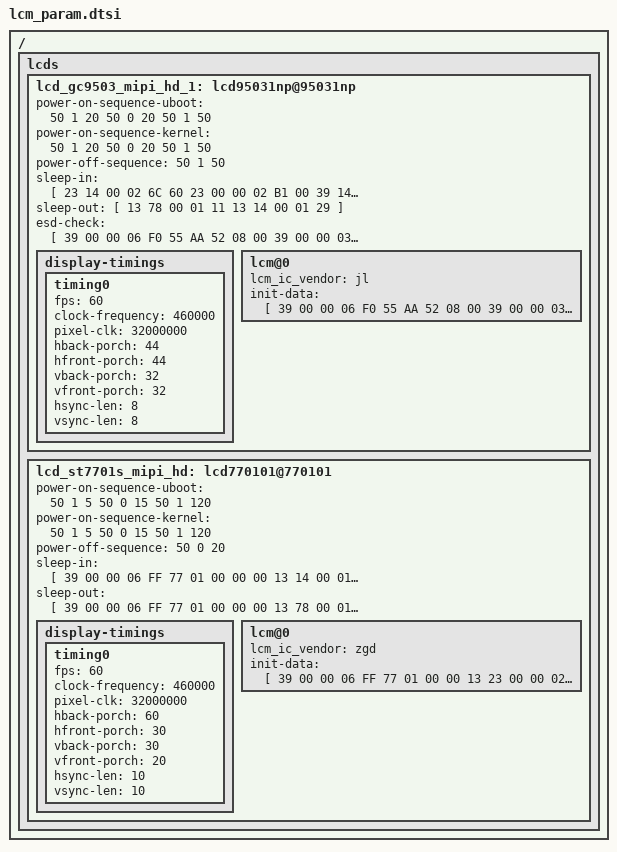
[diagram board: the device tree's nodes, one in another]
/ {
	lcds {

		lcd_gc9503_mipi_hd_1: lcd95031np@95031np {

		power-on-sequence-uboot = <//first level second delay ms
					50  1  20
					50  0  20
					50  1  50
					>;

		power-on-sequence-kernel = <
					50  1  20
					50  0  20
					50  1  50
					>;

		power-off-sequence = <
					50  1  50
					>;

		sleep-in = [
			23 14 00 02 6C 60
			23 00 00 02 B1 00
			39 14 00 05 FA 7F 00 00 00
			23 0a 00 02 6c 50
			23 32 00 02 28 00
			23 78 00 02 10 00
			39 00 00 06 F0 55 aa 52 08 00
			23 00 00 02 c2 ce
			23 00 00 02 c3 cd
			23 00 00 02 c6 fc
			23 00 00 02 c5 03
			23 00 00 02 cd 64
			23 00 00 02 c4 ff
			23 00 00 02 c9 cd
			39 00 00 03 F6 5a 87
			39 00 00 04 Fd aa aa 0a
			39 00 00 03 Fe 6a 0a
			39 00 00 03 78 2a aa
			39 00 00 03 92 17 08
			39 00 00 03 77 aa 2a
			39 00 00 03 76 aa aa
			23 00 00 02 84 00
			39 00 00 03 78 2b ba
			23 00 00 02 89 73
			23 00 00 02 88 3A
			23 00 00 02 85 B0
			39 00 00 03 76 eb aa
			23 00 00 02 94 80
			39 00 00 04 87 04 07 30
			23 00 00 02 93 27
			23 00 00 02 af 02
			];

		sleep-out = [
			13 78 00 01 11
			13 14 00 01 29
			];

		esd-check = [
			39 00 00 06 F0 55 AA 52 08 00
			39 00 00 03 F6 5A 87
			23 00 00 02 C1 3F
			23 00 00 02 C2 0E
			23 00 00 02 C6 F8
			23 00 00 02 C9 10
			23 00 00 02 CD 25
			39 00 00 04 87 04 03 66
			39 00 00 05 86 99 a3 a3 51
			23 00 00 02 F8 8A
			23 00 00 02 AC 45
			23 00 00 02 A7 47
			23 00 00 02 A0 dd
			39 00 00 05 FA 08 08 00 04
			23 00 00 02 A3 2E
			39 00 00 04 FD 28 3c 00
			23 00 00 02 71 48
			23 00 00 02 72 48
			39 00 00 03 73 00 44
			23 00 00 02 97 EE
			23 00 00 02 83 93
			23 00 00 02 B1 10
			39 00 00 03 7A 13 1A
			39 00 00 03 7B 13 1A
			39 00 00 11 64 18 09 03 59 03 03 18 08 03 5A 03 03 7A 7A 7A 7A
			39 00 00 11 67 18 07 03 5B 03 03 18 06 03 5C 03 03 7A 7A 7A 7A
			39 00 00 0E 68 00 08 0A 08 09 00 00 08 0A 08 09 00 00
			39 00 00 09 60 18 08 7A 7A 18 02 7A 7A
			39 00 00 09 63 18 02 6D 6D 18 07 7A 7A
			39 00 00 08 69 14 22 14 22 44 22 08
			23 00 00 02 6B 07
			23 00 00 02 38 00
			13 00 00 01 11
			13 00 00 01 29
			];

		display-timings {
			timing0 {
				fps = <60>;
				clock-frequency = <460000>;
				pixel-clk = <32000000>;	/* kbps */
				hback-porch = <44>;
				hfront-porch = <44>;
				vback-porch = <32>;
				vfront-porch = <32>;
				hsync-len = <8>;
				vsync-len = <8>;
			};
		};

		lcm@0 {

			lcm_ic_vendor= "jl";

			init-data = [
				39 00 00 06 F0 55 AA 52 08 00
				39 00 00 03 F6 5A 87
				23 00 00 02 C1 3F
				23 00 00 02 C2 0E
				23 00 00 02 C6 F8
				23 00 00 02 C9 10
				23 00 00 02 CD 25
				39 00 00 04 87 04 03 66
				39 00 00 05 86 99 a3 a3 51
				23 00 00 02 F8 8A
				23 00 00 02 AC 45
				23 00 00 02 A7 47
				23 00 00 02 A0 dd
				39 00 00 05 FA 08 08 00 04
				23 00 00 02 A3 2E
				39 00 00 04 FD 28 3c 00
				23 00 00 02 71 48
				23 00 00 02 72 48
				39 00 00 03 73 00 44
				23 00 00 02 97 EE
				23 00 00 02 83 93
				23 00 00 02 B1 10
				39 00 00 03 7A 13 1A
				39 00 00 03 7B 13 1A
				39 00 00 11 64 18 09 03 59 03 03 18 08 03 5A 03 03 7A 7A 7A 7A
				39 00 00 11 67 18 07 03 5B 03 03 18 06 03 5C 03 03 7A 7A 7A 7A
				39 00 00 0E 68 00 08 0A 08 09 00 00 08 0A 08 09 00 00
				39 00 00 09 60 18 08 7A 7A 18 02 7A 7A
				39 00 00 09 63 18 02 6D 6D 18 07 7A 7A
				39 00 00 08 69 14 22 14 22 44 22 08
				39 00 00 35 D1 00 00 00 08 00 1D 00 5F 00 91 00 CE 00 F5 01 2B 01 7f 01 ed 02 23 02 78 02 b2 02 b4 02 f1 03 29 03 49 03 6d 03 82 03 9b 03 A5 03 B0 03 B5 03 BF 03 DE 03 FF
				39 00 00 35 D2 00 00 00 08 00 1D 00 5F 00 91 00 CE 00 F5 01 2B 01 7f 01 ed 02 23 02 78 02 b2 02 b4 02 f1 03 29 03 49 03 6d 03 82 03 9b 03 A5 03 B0 03 B5 03 BF 03 DE 03 FF
				39 00 00 35 D3 00 00 00 08 00 1D 00 5F 00 91 00 CE 00 F5 01 2B 01 7f 01 ed 02 23 02 78 02 b2 02 b4 02 f1 03 29 03 49 03 6d 03 82 03 9b 03 A5 03 B0 03 B5 03 BF 03 DE 03 FF
				39 00 00 35 D4 00 00 00 08 00 1D 00 5F 00 91 00 CE 00 F5 01 2B 01 7f 01 ed 02 23 02 78 02 b2 02 b4 02 f1 03 29 03 49 03 6d 03 82 03 9b 03 A5 03 B0 03 B5 03 BF 03 DE 03 FF
				39 00 00 35 D5 00 00 00 08 00 1D 00 5F 00 91 00 CE 00 F5 01 2B 01 7f 01 ed 02 23 02 78 02 b2 02 b4 02 f1 03 29 03 49 03 6d 03 82 03 9b 03 A5 03 B0 03 B5 03 BF 03 DE 03 FF
				39 00 00 35 D6 00 00 00 08 00 1D 00 5F 00 91 00 CE 00 F5 01 2B 01 7f 01 ed 02 23 02 78 02 b2 02 b4 02 f1 03 29 03 49 03 6d 03 82 03 9b 03 A5 03 B0 03 B5 03 BF 03 DE 03 FF
				13 78 00 01 11
				13 14 00 01 29
				];
			};
		};

		lcd_st7701s_mipi_hd: lcd770101@770101 {

		power-on-sequence-uboot = <//first level second delay ms
					50  1  5
					50  0  15
					50  1  120
					>;

		power-on-sequence-kernel = <
					50  1  5
					50  0  15
					50  1  120
					>;

		power-off-sequence = <
					50  0  20
					>;

		sleep-in = [
			39 00 00 06 FF 77 01 00 00 00
			13 14 00 01 28
			13 78 00 01 10
			];

		sleep-out = [
			39 00 00 06 FF 77 01 00 00 00
			13 78 00 01 11
			13 14 00 01 29
			];

		display-timings {
			timing0 {
				fps = <60>;
				clock-frequency = <460000>;
				pixel-clk = <32000000>;	/* kbps */
				hback-porch = <60>;
				hfront-porch = <30>;
				vback-porch = <30>;
				vfront-porch = <20>;
				hsync-len = <10>;
				vsync-len = <10>;
			};
		};

		lcm@0 {

			lcm_ic_vendor= "zgd";

			init-data = [
				39 00 00 06 FF 77 01 00 00 13
				23 00 00 02 EF 08
				39 00 00 06 FF 77 01 00 00 10
				39 00 00 03 C0 E9 03
				39 00 00 03 C1 11 02
				39 00 00 03 C2 37 08
				23 00 00 02 CC 10
				39 00 00 11 B0 00 06 13 14 1A 0A 12 09 09 24 02 0C 0F 0A 0F 1F
				39 00 00 11 B1 00 08 13 14 18 0B 11 08 08 27 08 15 11 21 23 1F
				39 00 00 06 FF 77 01 00 00 11
				23 00 00 02 B0 65
				23 00 00 02 B1 3D
				23 00 00 02 B2 87
				23 00 00 02 B3 80
				23 00 00 02 B5 47
				23 00 00 02 B7 85
				23 00 00 02 B8 21
				23 00 00 02 B9 10
				23 00 00 02 C1 78
				23 00 00 02 C2 78
				23 00 00 02 D0 88
				39 00 00 04 E0 00 00 02
				39 00 00 0C E1 08 00 0A 00 07 00 09 00 00 33 33
				39 00 00 0E E2 00 00 00 00 00 00 00 00 00 00 00 00 00
				39 00 00 05 E3 00 00 33 33
				39 00 00 03 E4 44 44
				39 00 00 11 E5 0E 60 A0 A0 10 60 A0 A0 0A 60 A0 A0 0C 60 A0 A0
				39 00 00 05 E6 00 00 33 33
				39 00 00 03 E7 44 44
				39 00 00 11 E8 0D 60 A0 A0 0F 60 A0 A0 09 60 A0 A0 0B 60 A0 A0
				39 00 00 08 EB 02 01 E4 E4 44 00 40
				39 00 00 03 EC 02 01
				39 00 00 11 ED AB 89 76 54 01 FF FF FF FF FF FF 10 45 67 98 BA
				39 00 00 07 EF 08 08 08 45 3F 54
				39 00 00 06 FF 77 01 00 00 13
				39 00 00 03 E6 16 7C
				39 00 00 03 E8 00 0E
				39 00 00 06 FF 77 01 00 00 00
				23 00 00 02 35 00
				23 78 00 02 11 00
				39 00 00 06 FF 77 01 00 00 13
				39 0A 00 03 E8 00 0C
				39 00 00 03 E8 00 00
				39 00 00 06 FF 77 01 00 00 00
				23 14 00 02 29 00
				];
			};
		};


	};
};
